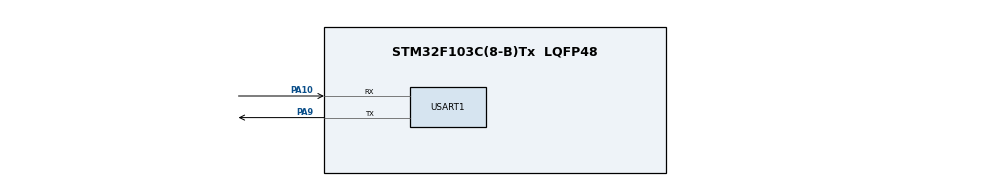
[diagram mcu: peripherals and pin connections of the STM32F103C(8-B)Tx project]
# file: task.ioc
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FREERTOS.Tasks01=defaultTask,24,128,StartDefaultTask,Default,NULL,Dynamic,NULL,NULL;myTask02,24,128,StartTask02,Default,NULL,Dynamic,NULL,NULL
FREERTOS.configUSE_NEWLIB_REENTRANT=1
Mcu.Family=STM32F1
Mcu.Name=STM32F103C(8-B)Tx
Mcu.Package=LQFP48
NVIC.PriorityGroup=NVIC_PRIORITYGROUP_4
NVIC.TIM2_IRQn=true\:15\:0\:false\:false\:true\:false\:false\:true\:true
NVIC.TimeBase=TIM2_IRQn
NVIC.TimeBaseIP=TIM2
PA10.Mode=Asynchronous
PA10.Signal=USART1_RX
PA13.Mode=Serial_Wire
PA13.Signal=SYS_JTMS-SWDIO
PA14.Mode=Serial_Wire
PA14.Signal=SYS_JTCK-SWCLK
PA9.Mode=Asynchronous
PA9.Signal=USART1_TX
PD0-OSC_IN.Mode=HSE-External-Oscillator
PD0-OSC_IN.Signal=RCC_OSC_IN
PD1-OSC_OUT.Mode=HSE-External-Oscillator
PD1-OSC_OUT.Signal=RCC_OSC_OUT
ProjectManager.HeapSize=0x200
ProjectManager.StackSize=0x400
ProjectManager.TargetToolchain=STM32CubeIDE
RCC.APB1Freq_Value=8000000
RCC.APB2Freq_Value=8000000
USART1.VirtualMode=VM_ASYNC
VP_FREERTOS_VS_CMSIS_V2.Mode=CMSIS_V2
VP_SYS_VS_tim2.Mode=TIM2
board=custom

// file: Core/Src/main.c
/* USER CODE BEGIN Header */
/**
  ******************************************************************************
  * @file           : main.c
  * @brief          : Main program body
  ******************************************************************************
  * @attention
  *
  * Copyright (c) 2023 STMicroelectronics.
  * All rights reserved.
  *
  * This software is licensed under terms that can be found in the LICENSE file
  * in the root directory of this software component.
  * If no LICENSE file comes with this software, it is provided AS-IS.
  *
  ******************************************************************************
  */
/* USER CODE END Header */
#include "main.h"
#include "cmsis_os.h"
#include "usart.h"
#include "gpio.h"

void SystemClock_Config(void);
void MX_FREERTOS_Init(void);

int main(void)
{

  /* MCU Configuration--------------------------------------------------------*/

  /* Reset of all peripherals, Initializes the Flash interface and the Systick. */
  HAL_Init();

  /* Configure the system clock */
  SystemClock_Config();

  /* Initialize all configured peripherals */
  MX_GPIO_Init();
  MX_USART1_UART_Init();

  /* Init scheduler */
  osKernelInitialize();  /* Call init function for freertos objects (in freertos.c) */
  MX_FREERTOS_Init();

  /* Start scheduler */
  osKernelStart();

  /* We should never get here as control is now taken by the scheduler */
  /* Infinite loop */
  while (1)
  {

  }
}

void SystemClock_Config(void)
{
  RCC_OscInitTypeDef RCC_OscInitStruct = {0};
  RCC_ClkInitTypeDef RCC_ClkInitStruct = {0};

  /** Initializes the RCC Oscillators according to the specified parameters
  * in the RCC_OscInitTypeDef structure.
  */
  RCC_OscInitStruct.OscillatorType = RCC_OSCILLATORTYPE_HSI;
  RCC_OscInitStruct.HSIState = RCC_HSI_ON;
  RCC_OscInitStruct.HSICalibrationValue = RCC_HSICALIBRATION_DEFAULT;
  RCC_OscInitStruct.PLL.PLLState = RCC_PLL_NONE;
  if (HAL_RCC_OscConfig(&RCC_OscInitStruct) != HAL_OK)
  {
    Error_Handler();
  }

  /** Initializes the CPU, AHB and APB buses clocks
  */
  RCC_ClkInitStruct.ClockType = RCC_CLOCKTYPE_HCLK|RCC_CLOCKTYPE_SYSCLK
                              |RCC_CLOCKTYPE_PCLK1|RCC_CLOCKTYPE_PCLK2;
  RCC_ClkInitStruct.SYSCLKSource = RCC_SYSCLKSOURCE_HSI;
  RCC_ClkInitStruct.AHBCLKDivider = RCC_SYSCLK_DIV1;
  RCC_ClkInitStruct.APB1CLKDivider = RCC_HCLK_DIV1;
  RCC_ClkInitStruct.APB2CLKDivider = RCC_HCLK_DIV1;

  if (HAL_RCC_ClockConfig(&RCC_ClkInitStruct, FLASH_LATENCY_0) != HAL_OK)
  {
    Error_Handler();
  }
}

void HAL_TIM_PeriodElapsedCallback(TIM_HandleTypeDef *htim)
{
  if (htim->Instance == TIM2) {
    HAL_IncTick();
  }
}

void Error_Handler(void)
{
  __disable_irq();
  while (1)
  {
  }
}

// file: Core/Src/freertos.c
/* USER CODE BEGIN Header */
/**
  ******************************************************************************
  * File Name          : freertos.c
  * Description        : Code for freertos applications
  ******************************************************************************
  * @attention
  *
  * Copyright (c) 2023 STMicroelectronics.
  * All rights reserved.
  *
  * This software is licensed under terms that can be found in the LICENSE file
  * in the root directory of this software component.
  * If no LICENSE file comes with this software, it is provided AS-IS.
  *
  ******************************************************************************
  */
/* USER CODE END Header */

#include "FreeRTOS.h"
#include "task.h"
#include "main.h"
#include "cmsis_os.h"
#include "usart.h"

/* Definitions for defaultTask */
osThreadId_t defaultTaskHandle;
const osThreadAttr_t defaultTask_attributes = {
    .name = "defaultTask",
    .stack_size = 128 * 4,
    .priority = (osPriority_t) osPriorityNormal,
};
/* Definitions for myTask02 */
osThreadId_t myTask02Handle;
const osThreadAttr_t myTask02_attributes = {
    .name = "myTask02",
    .stack_size = 128 * 4,
    .priority = (osPriority_t) osPriorityNormal,
};

void StartDefaultTask(void *argument);
void StartTask02(void *argument);

void MX_FREERTOS_Init(void); /* (MISRA C 2004 rule 8.1) */

void MX_FREERTOS_Init(void)
{

    /* Create the thread(s) */
    /* creation of defaultTask */
    defaultTaskHandle = osThreadNew(StartDefaultTask, NULL, &defaultTask_attributes);

    /* creation of myTask02 */
    myTask02Handle = osThreadNew(StartTask02, NULL, &myTask02_attributes);

}

void StartDefaultTask(void *argument)
{
    /* USER CODE BEGIN StartDefaultTask */
    /* Infinite loop */
    for (;;) {
        HAL_UART_Transmit(&huart1, (uint8_t *) "hello world1\r\n", 15, 100);
        HAL_Delay(1000);
    }
    /* USER CODE END StartDefaultTask */
}

void StartTask02(void *argument)
{
    /* USER CODE BEGIN StartTask02 */
    /* Infinite loop */
    for (;;) {
        HAL_UART_Transmit(&huart1, (uint8_t *) "hello world2\r\n", 15, 100);
        HAL_Delay(1000);
    }
    /* USER CODE END StartTask02 */
}
